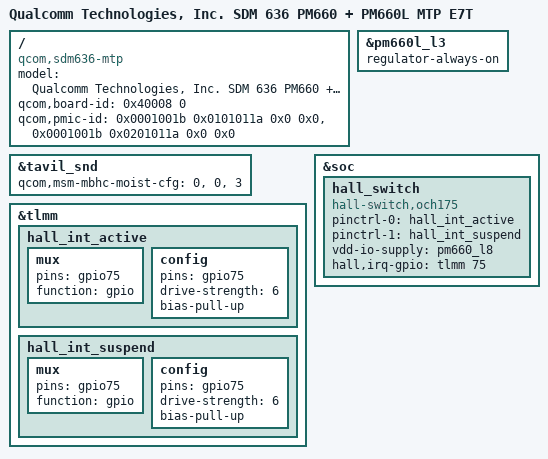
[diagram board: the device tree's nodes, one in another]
/* Copyright (c) 2017, The Linux Foundation. All rights reserved.
 * Copyright (C) 2018 XiaoMi, Inc.
 *
 * This program is free software; you can redistribute it and/or modify
 * it under the terms of the GNU General Public License version 2 and
 * only version 2 as published by the Free Software Foundation.
 *
 * This program is distributed in the hope that it will be useful,
 * but WITHOUT ANY WARRANTY; without even the implied warranty of
 * MERCHANTABILITY or FITNESS FOR A PARTICULAR PURPOSE.  See the
 * GNU General Public License for more details.
 */


/dts-v1/;

#include "sdm636.dtsi"
#include "sdm636-mtp.dtsi"
#include "sdm660-internal-codec.dtsi"
#include "tulip/focaltech-ft8719-i2c.dtsi"
#include "tulip/SAR-sensor-regulator-tulip.dtsi"

/ {
	model = "Qualcomm Technologies, Inc. SDM 636 PM660 + PM660L MTP E7T";
	compatible = "qcom,sdm636-mtp", "qcom,sdm636", "qcom,mtp";
	qcom,board-id = <0x40008 0>;
	qcom,pmic-id = <0x0001001b 0x0101011a 0x0 0x0>,
			<0x0001001b 0x0201011a 0x0 0x0>;
};

&tavil_snd {
	qcom,msm-mbhc-moist-cfg = <0>, <0>, <3>;
};
&pm660l_l3 {
        regulator-always-on;
};
&tlmm {
	hall_int_active:hall_int_active {
		mux {
		          pins = "gpio75";
		          function = "gpio";
		};
		config{
		          pins = "gpio75";
	                  drive-strength = <6>;
	                  bias-pull-up;
	            };
        };
	hall_int_suspend: hall_int_suspend {
		mux {
		          pins = "gpio75";
		          function = "gpio";
		};
		config{
		          pins = "gpio75";
		          drive-strength = <6>;
		          bias-pull-up;
		};
        };
};
&soc {
	hall_switch {

	    compatible = "hall-switch,och175";
	    pinctrl-names = "hall_active","hall_suspend";
	    pinctrl-0 = <&hall_int_active>;
	    pinctrl-1 = <&hall_int_suspend>;
	    //interrupt-parent = <&msm_gpio>;
	    //interrupts = <0 107 3>;
	    vdd-io-supply= <&pm660_l8>;
	    interrupt-names = "hall_irq";
	    hall,irq-gpio = <&tlmm 75 0x0>;
	};
};

#include "tulip/sdm636-tulip.dtsi"
#include "tulip/sdm660-tulip.dtsi"
#include "tulip/msm-pm660-tulip.dtsi"
#include "common/msm-pm660l.dtsi"
#include "common/sdm660-regulator.dtsi"
#include "tulip/sdm660-common-tulip.dtsi"
#include "common/sdm660-blsp.dtsi"
#include "common/sdm660-pinctrl.dtsi"
#include "common/sdm660-camera.dtsi"
#include "common/msm-audio.dtsi"
#include "common/sdm660-audio.dtsi"
#include "common/sdm660-mdss-panels.dtsi"
#include "tulip/sdm636-mtp-tulip.dtsi"
#include "tulip/sdm660-mtp-tulip.dtsi"
#include "tulip/sdm660-camera-sensor-mtp-tulip.dtsi"
#include "common/sdm660-internal-codec.dtsi"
